VERSION "blueprint-1"

NS_ :

BS_:

BU_: ClimateECU BMS HeadUnit

CM_ "Signal database for the AOSP vertical blueprint. Edit here first when adding a vehicle signal.";

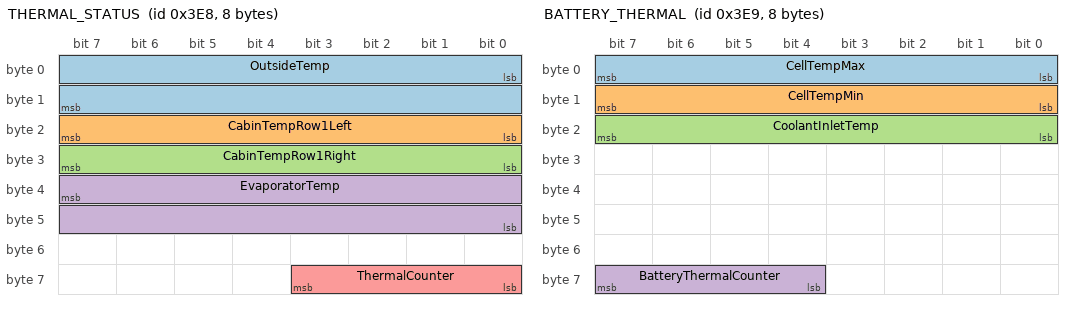
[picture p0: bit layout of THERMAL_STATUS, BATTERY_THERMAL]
BO_ 1000 THERMAL_STATUS: 8 ClimateECU
 SG_ OutsideTemp : 0|16@1+ (0.1,-40) [-40|125] "degC" HeadUnit
 SG_ CabinTempRow1Left : 16|8@1+ (0.5,-10) [-10|117.5] "degC" HeadUnit
 SG_ CabinTempRow1Right : 24|8@1+ (0.5,-10) [-10|117.5] "degC" HeadUnit
 SG_ EvaporatorTemp : 39|16@0- (0.01,0) [-50|150] "degC" HeadUnit
 SG_ ThermalCounter : 56|4@1+ (1,0) [0|15] "" HeadUnit

BO_ 1001 BATTERY_THERMAL: 8 BMS
 SG_ CellTempMax : 0|8@1+ (1,-40) [-40|125] "degC" HeadUnit
 SG_ CellTempMin : 8|8@1+ (1,-40) [-40|125] "degC" HeadUnit
 SG_ CoolantInletTemp : 16|8@1+ (1,-40) [-40|125] "degC" HeadUnit
 SG_ BatteryThermalCounter : 60|4@1+ (1,0) [0|15] "" HeadUnit

CM_ SG_ 1000 OutsideTemp "Ambient temperature from the front bumper NTC.";
CM_ SG_ 1000 EvaporatorTemp "Big-endian (Motorola) signed example.";
CM_ SG_ 1000 ThermalCounter "Rolling counter, increments every frame.";
CM_ SG_ 1001 CellTempMax "Hottest cell in the HV battery pack. Worked example in docs/vhal/adding-a-new-signal.md.";

BA_DEF_ SG_ "VhalProperty" STRING ;
BA_DEF_ SG_ "VhalAreaId" INT 0 2147483647;
BA_DEF_ SG_ "VhalChangeMode" ENUM "ON_CHANGE","CONTINUOUS";
BA_DEF_ SG_ "VhalMinSampleRate" FLOAT 0 1000;
BA_DEF_ SG_ "VhalMaxSampleRate" FLOAT 0 1000;
BA_DEF_DEF_ "VhalProperty" "";
BA_DEF_DEF_ "VhalAreaId" 0;
BA_DEF_DEF_ "VhalChangeMode" "ON_CHANGE";
BA_DEF_DEF_ "VhalMinSampleRate" 1;
BA_DEF_DEF_ "VhalMaxSampleRate" 10;

BA_ "VhalProperty" SG_ 1000 OutsideTemp "ENV_OUTSIDE_TEMPERATURE";
BA_ "VhalChangeMode" SG_ 1000 OutsideTemp "CONTINUOUS";
BA_ "VhalMaxSampleRate" SG_ 1000 OutsideTemp 2;
BA_ "VhalProperty" SG_ 1000 CabinTempRow1Left "HVAC_TEMPERATURE_CURRENT";
BA_ "VhalAreaId" SG_ 1000 CabinTempRow1Left 49;
BA_ "VhalProperty" SG_ 1000 CabinTempRow1Right "HVAC_TEMPERATURE_CURRENT";
BA_ "VhalAreaId" SG_ 1000 CabinTempRow1Right 68;
BA_ "VhalProperty" SG_ 1001 CellTempMax "VENDOR_BATTERY_CELL_TEMP_MAX";
